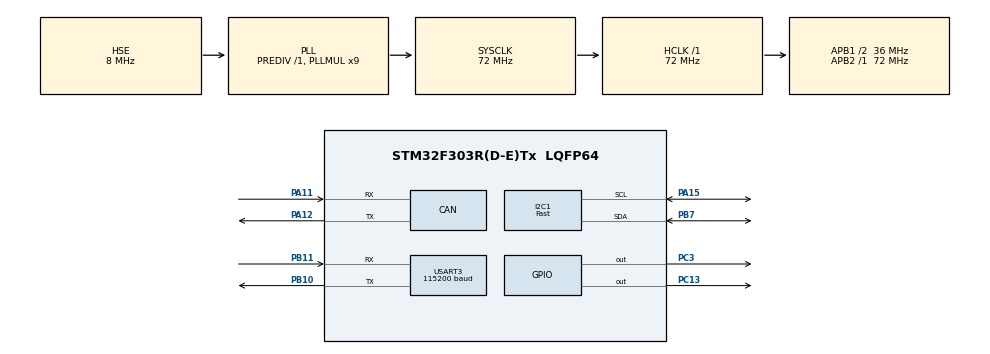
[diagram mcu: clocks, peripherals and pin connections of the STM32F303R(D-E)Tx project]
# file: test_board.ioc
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CAN.BS1=CAN_BS1_1TQ
CAN.BS2=CAN_BS2_1TQ
CAN.CalculateTimeQuantum=444.44444444444446
I2C1.I2C_Speed_Mode=I2C_Fast
I2C1.Timing=0x0000020B
Mcu.Family=STM32F3
Mcu.Name=STM32F303R(D-E)Tx
Mcu.Package=LQFP64
NVIC.PriorityGroup=NVIC_PRIORITYGROUP_4
PA11.Mode=Master
PA11.Signal=CAN_RX
PA12.Mode=Master
PA12.Signal=CAN_TX
PA13.Mode=Serial_Wire
PA13.Signal=SYS_JTMS-SWDIO
PA14.Mode=Serial_Wire
PA14.Signal=SYS_JTCK-SWCLK
PA15.Mode=I2C
PA15.Signal=I2C1_SCL
PB10.Mode=Asynchronous
PB10.Signal=USART3_TX
PB11.Mode=Asynchronous
PB11.Signal=USART3_RX
PB7.Mode=I2C
PB7.Signal=I2C1_SDA
PC13.Signal=GPIO_Output
PC3.Signal=GPIO_Output
PF0-OSC_IN.Mode=HSE-External-Oscillator
PF0-OSC_IN.Signal=RCC_OSC_IN
PF1-OSC_OUT.Mode=HSE-External-Oscillator
PF1-OSC_OUT.Signal=RCC_OSC_OUT
ProjectManager.HeapSize=0x200
ProjectManager.StackSize=0x400
ProjectManager.TargetToolchain=STM32CubeIDE
RCC.AHBFreq_Value=72000000
RCC.APB1CLKDivider=RCC_HCLK_DIV2
RCC.APB1Freq_Value=36000000
RCC.APB1TimFreq_Value=72000000
RCC.APB2Freq_Value=72000000
RCC.APB2TimFreq_Value=72000000
RCC.CortexFreq_Value=72000000
RCC.HCLKFreq_Value=72000000
RCC.HSE_VALUE=8000000
RCC.HSI_VALUE=8000000
RCC.LSE_VALUE=32768
RCC.PLLMUL=RCC_PLL_MUL9
RCC.PLLSourceVirtual=RCC_PLLSOURCE_HSE
RCC.SYSCLKFreq_VALUE=72000000
RCC.SYSCLKSourceVirtual=RCC_SYSCLKSOURCE_PLLCLK
RCC.USBFreq_Value=72000000
USART3.BaudRate=115200
USART3.VirtualMode-Asynchronous=VM_ASYNC
board=custom

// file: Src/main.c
/* USER CODE BEGIN Header */
/**
  ******************************************************************************
  * @file           : main.c
  * @brief          : Main program body
  ******************************************************************************
  * @attention
  *
  * <h2><center>&copy; Copyright (c) 2019 STMicroelectronics.
  * All rights reserved.</center></h2>
  *
  * This software component is licensed by ST under BSD 3-Clause license,
  * the "License"; You may not use this file except in compliance with the
  * License. You may obtain a copy of the License at:
  *                        opensource.org/licenses/BSD-3-Clause
  *
  ******************************************************************************
  */
/* USER CODE END Header */

#include "main.h"

CAN_HandleTypeDef hcan;

I2C_HandleTypeDef hi2c1;

UART_HandleTypeDef huart3;

void SystemClock_Config(void);
static void MX_GPIO_Init(void);
static void MX_CAN_Init(void);
static void MX_I2C1_Init(void);
static void MX_USART3_UART_Init(void);

int main(void)
{

  /* MCU Configuration--------------------------------------------------------*/

  /* Reset of all peripherals, Initializes the Flash interface and the Systick. */
  HAL_Init();

  /* Configure the system clock */
  SystemClock_Config();

  /* Initialize all configured peripherals */
  MX_GPIO_Init();
  MX_CAN_Init();
  MX_I2C1_Init();
  MX_USART3_UART_Init();
  /* USER CODE BEGIN 2 */
  init_MPU();
  /* USER CODE END 2 */

  /* Infinite loop */
  while (1)
  {

    /* USER CODE BEGIN 3 */
//	  HAL_GPIO_TogglePin(GPIOC,GPIO_PIN_13);
//	  HAL_GPIO_TogglePin(GPIOC,GPIO_PIN_3);
//	  HAL_Delay(1000);
	  process_MPU();

//	  for(int i =0; i<= 256; i++){
//		  char rx_data[25] = "";
//		  if (HAL_I2C_IsDeviceReady(&hi2c1, i , 3, 20) != HAL_OK) {
//		     	strcpy( rx_data, ".");
//		       }
//		       else{
//		     	  strcpy( rx_data, "Device found");
//		       }
//		  HAL_UART_Transmit(&huart3,rx_data, strlen(rx_data),1000);
//		  HAL_Delay(1);
//	  }
  }
  /* USER CODE END 3 */
}

void SystemClock_Config(void)
{
  RCC_OscInitTypeDef RCC_OscInitStruct = {0};
  RCC_ClkInitTypeDef RCC_ClkInitStruct = {0};
  RCC_PeriphCLKInitTypeDef PeriphClkInit = {0};

  /** Initializes the CPU, AHB and APB busses clocks
  */
  RCC_OscInitStruct.OscillatorType = RCC_OSCILLATORTYPE_HSI|RCC_OSCILLATORTYPE_HSE;
  RCC_OscInitStruct.HSEState = RCC_HSE_ON;
  RCC_OscInitStruct.HSIState = RCC_HSI_ON;
  RCC_OscInitStruct.HSICalibrationValue = RCC_HSICALIBRATION_DEFAULT;
  RCC_OscInitStruct.PLL.PLLState = RCC_PLL_ON;
  RCC_OscInitStruct.PLL.PLLSource = RCC_PLLSOURCE_HSE;
  RCC_OscInitStruct.PLL.PLLMUL = RCC_PLL_MUL9;
  RCC_OscInitStruct.PLL.PREDIV = RCC_PREDIV_DIV1;
  if (HAL_RCC_OscConfig(&RCC_OscInitStruct) != HAL_OK)
  {
    Error_Handler();
  }
  /** Initializes the CPU, AHB and APB busses clocks
  */
  RCC_ClkInitStruct.ClockType = RCC_CLOCKTYPE_HCLK|RCC_CLOCKTYPE_SYSCLK
                              |RCC_CLOCKTYPE_PCLK1|RCC_CLOCKTYPE_PCLK2;
  RCC_ClkInitStruct.SYSCLKSource = RCC_SYSCLKSOURCE_PLLCLK;
  RCC_ClkInitStruct.AHBCLKDivider = RCC_SYSCLK_DIV1;
  RCC_ClkInitStruct.APB1CLKDivider = RCC_HCLK_DIV2;
  RCC_ClkInitStruct.APB2CLKDivider = RCC_HCLK_DIV1;

  if (HAL_RCC_ClockConfig(&RCC_ClkInitStruct, FLASH_LATENCY_2) != HAL_OK)
  {
    Error_Handler();
  }
  PeriphClkInit.PeriphClockSelection = RCC_PERIPHCLK_USART3|RCC_PERIPHCLK_I2C1;
  PeriphClkInit.Usart3ClockSelection = RCC_USART3CLKSOURCE_PCLK1;
  PeriphClkInit.I2c1ClockSelection = RCC_I2C1CLKSOURCE_HSI;
  if (HAL_RCCEx_PeriphCLKConfig(&PeriphClkInit) != HAL_OK)
  {
    Error_Handler();
  }
}

static void MX_CAN_Init(void)
{

  hcan.Instance = CAN;
  hcan.Init.Prescaler = 16;
  hcan.Init.Mode = CAN_MODE_NORMAL;
  hcan.Init.SyncJumpWidth = CAN_SJW_1TQ;
  hcan.Init.TimeSeg1 = CAN_BS1_1TQ;
  hcan.Init.TimeSeg2 = CAN_BS2_1TQ;
  hcan.Init.TimeTriggeredMode = DISABLE;
  hcan.Init.AutoBusOff = DISABLE;
  hcan.Init.AutoWakeUp = DISABLE;
  hcan.Init.AutoRetransmission = DISABLE;
  hcan.Init.ReceiveFifoLocked = DISABLE;
  hcan.Init.TransmitFifoPriority = DISABLE;
  if (HAL_CAN_Init(&hcan) != HAL_OK)
  {
    Error_Handler();
  }

}

static void MX_I2C1_Init(void)
{

  hi2c1.Instance = I2C1;
  hi2c1.Init.Timing = 0x0000020B;
  hi2c1.Init.OwnAddress1 = 0;
  hi2c1.Init.AddressingMode = I2C_ADDRESSINGMODE_7BIT;
  hi2c1.Init.DualAddressMode = I2C_DUALADDRESS_DISABLE;
  hi2c1.Init.OwnAddress2 = 0;
  hi2c1.Init.OwnAddress2Masks = I2C_OA2_NOMASK;
  hi2c1.Init.GeneralCallMode = I2C_GENERALCALL_DISABLE;
  hi2c1.Init.NoStretchMode = I2C_NOSTRETCH_DISABLE;
  if (HAL_I2C_Init(&hi2c1) != HAL_OK)
  {
    Error_Handler();
  }
  /** Configure Analogue filter
  */
  if (HAL_I2CEx_ConfigAnalogFilter(&hi2c1, I2C_ANALOGFILTER_ENABLE) != HAL_OK)
  {
    Error_Handler();
  }
  /** Configure Digital filter
  */
  if (HAL_I2CEx_ConfigDigitalFilter(&hi2c1, 0) != HAL_OK)
  {
    Error_Handler();
  }

}

static void MX_USART3_UART_Init(void)
{

  huart3.Instance = USART3;
  huart3.Init.BaudRate = 115200;
  huart3.Init.WordLength = UART_WORDLENGTH_8B;
  huart3.Init.StopBits = UART_STOPBITS_1;
  huart3.Init.Parity = UART_PARITY_NONE;
  huart3.Init.Mode = UART_MODE_TX_RX;
  huart3.Init.HwFlowCtl = UART_HWCONTROL_NONE;
  huart3.Init.OverSampling = UART_OVERSAMPLING_16;
  huart3.Init.OneBitSampling = UART_ONE_BIT_SAMPLE_DISABLE;
  huart3.AdvancedInit.AdvFeatureInit = UART_ADVFEATURE_NO_INIT;
  if (HAL_UART_Init(&huart3) != HAL_OK)
  {
    Error_Handler();
  }

}

static void MX_GPIO_Init(void)
{
  GPIO_InitTypeDef GPIO_InitStruct = {0};

  /* GPIO Ports Clock Enable */
  __HAL_RCC_GPIOC_CLK_ENABLE();
  __HAL_RCC_GPIOF_CLK_ENABLE();
  __HAL_RCC_GPIOB_CLK_ENABLE();
  __HAL_RCC_GPIOA_CLK_ENABLE();

  /*Configure GPIO pin Output Level */
  HAL_GPIO_WritePin(GPIOC, GPIO_PIN_13|GPIO_PIN_3, GPIO_PIN_RESET);

  /*Configure GPIO pins : PC13 PC3 */
  GPIO_InitStruct.Pin = GPIO_PIN_13|GPIO_PIN_3;
  GPIO_InitStruct.Mode = GPIO_MODE_OUTPUT_PP;
  GPIO_InitStruct.Pull = GPIO_NOPULL;
  GPIO_InitStruct.Speed = GPIO_SPEED_FREQ_LOW;
  HAL_GPIO_Init(GPIOC, &GPIO_InitStruct);

}

void Error_Handler(void)
{
}

/************************ (C) COPYRIGHT STMicroelectronics *****END OF FILE****/
